# M030GAE register map
File version: 1.0
Registers are 32-bit, read-write, reset 0x0 unless marked. A register's access mark holds for its fields unless they carry their own. Offsets are from the block's base; [hi:lo] are bit positions; 'fields as' and 'values as' point back to an identical list.

## DAC2 — DAC Register Map
Base 0x4004B000
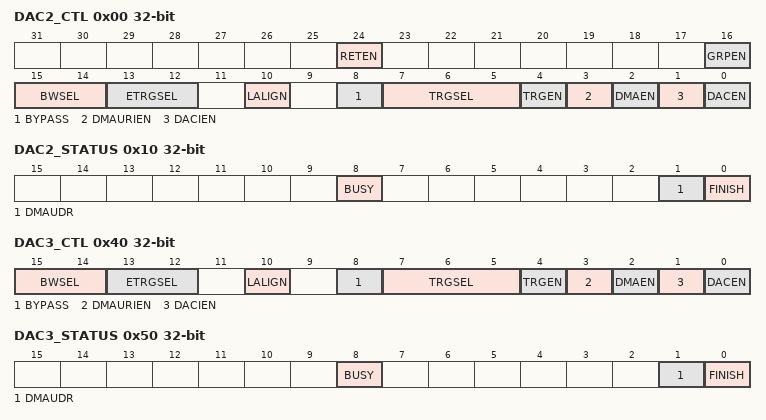
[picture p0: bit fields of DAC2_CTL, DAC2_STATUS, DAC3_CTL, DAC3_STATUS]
0x00 DAC2_CTL — DAC2 Control Register
  [24] RETEN — DAC Reset Retention Select (Write Protect). Note 1: This bit is write protected. Refer to the SYS_REGLCTL register. Note 2: This bit only exists in DAC0 control register to control 4 DAC retention.
    0=DAC controller registers reset by POR, NRESET, WDT, LVR, BOD, Lockup, CHIP and MCU reset sources; 1=DAC controller registers reset by POR, LVR, BOD and Lockup reset sources
  [16] GRPEN — DAC Group Mode Enable Bit
    0=DAC2 and DAC3 are not grouped; 1=DAC2 and DAC3 are grouped
  [15:14] BWSEL — DAC Data Bit-width Selection
    0=Data is 12 bits; 1=Data is 8 bits
  [13:12] ETRGSEL — External Pin Trigger Selection
    0=Low level trigger; 1=High level trigger; 2=Falling edge trigger; 3=Rising edge trigger
  [10] LALIGN — DAC Data Left-aligned Enabled Bit
    0=Right alignment; 1=Left alignment
  [8] BYPASS — Bypass Buffer Mode
    0=Output voltage buffer Enabled; 1=Output voltage buffer Disabled
  [7:5] TRGSEL — Trigger Source Selection
    0=Software trigger; 1=Timer 2 trigger; 2=Timer 0 trigger; 3=Timer 1 trigger; 4=Timer 3 trigger; 5=Timer 4 trigger; 6=BPWM 1 trigger; 7=Timer 5 trigger
  [4] TRGEN — Trigger Mode Enable Bit
    0=DAC event trigger mode Disabled; 1=DAC event trigger mode Enabled
  [3] DMAURIEN — DMA Under-run Interrupt Enable Bit
    0=DMA under-run interrupt Disabled; 1=DMA under-run interrupt Enabled
  [2] DMAEN — DMA Mode Enable Bit
    0=DMA mode Disabled; 1=DMA mode Enabled
  [1] DACIEN — DAC Interrupt Enable Bit
    0=DAC interrupt Disabled; 1=DAC interrupt Enabled
  [0] DACEN — DAC Enable Bit
    0=DAC Disabled; 1=DAC Enabled
0x04 DAC2_SWTRG — DAC2 Software Trigger Control Register
  [0] SWTRG — Software Trigger. Note: Writing this bit will generate one shot pulse and this bit is cleared to 0 by hardware automatically; reading this bit will always get 0.
    0=Software trigger Disabled; 1=Software trigger Enabled
0x08 DAC2_DAT — DAC2 Data Holding Register
  [15:0] DACDAT — DAC 12-bit Holding Data. These bits are written by user software which specifies 12-bit conversion data for DAC output. The unused bits (DAC2_DAT[3:0] in left-alignment mode and DAC2_DAT[15:12] in right alignment mode) are ignored by DAC controller hardware. 12 bit left alignment: user has to load data into DAC2_DAT[15:4] bits. 12 bit right alignment: user has to load data into DAC2_DAT[11:0] bits.
0x0C DAC2_DATOUT ro — DAC2 Data Output Register
  [11:0] DATOUT — DAC 12-bit Output Data. These bits are current digital data for DAC output conversion. It is loaded from DAC2_DAT register and user cannot write it directly.
0x10 DAC2_STATUS
  [8] BUSY ro — DAC Busy Flag (Read Only)
    0=DAC is ready for next conversion; 1=DAC is busy in conversion
  [1] DMAUDR — DMA Under-run Interrupt Flag. Note: Write 1 to clear this bit.
    0=No DMA under-run error condition occurred; 1=DMA under-run error condition occurred
  [0] FINISH — DAC Conversion Complete Finish Flag. Note: This bit is set to 1 when conversion time counter counts to SETTLET. It is cleared to 0 when DAC starts a new conversion. Write 1 to clear this bit to 0.
    0=DAC is in conversion state; 1=DAC conversion finish
0x14 DAC2_TCTL — DAC2 Timing Control Register
  [9:0] SETTLET — DAC Output Conversion Cycles. User software needs to write appropriate value to these bits to meet DAC conversion settling time based on PCLK (APB clock) speed. For example, DAC controller clock speed is 72 MHz and DAC conversion setting time is 1 us, and SETTLET value must be greater than 0x48. Note: The DAC output Conversion cycles is SETTLET + 1 PCLK cycles.
0x40 DAC3_CTL — DAC3 Control Register
  [15:14] BWSEL — DAC Data Bit-width Selection
    0=Data is 12 bits; 1=Data is 8 bits
  [13:12] ETRGSEL — External Pin Trigger Selection
    values as DAC2_CTL.ETRGSEL
  [10] LALIGN — DAC Data Left-aligned Enable Control
    0=Right alignment; 1=Left alignment
  [8] BYPASS — Bypass Buffer Mode
    values as DAC2_CTL.BYPASS
  [7:5] TRGSEL — Trigger Source Selection
    values as DAC2_CTL.TRGSEL
  [4] TRGEN — Trigger Mode Enable Bit
    values as DAC2_CTL.TRGEN
  [3] DMAURIEN — DMA Under-run Interrupt Enable Bit
    values as DAC2_CTL.DMAURIEN
  [2] DMAEN — DMA Mode Enable Bit
    0=DMA mode Disabled; 1=DMA mode Enabled
  [1] DACIEN — DAC Interrupt Enable Bit
    0=DAC interrupt Disabled; 1=DAC interrupt Enabled
  [0] DACEN — DAC Enable Bit
    0=DAC Disabled; 1=DAC Enabled
0x44 DAC3_SWTRG — DAC3 Software Trigger Control Register
  fields as DAC2_SWTRG
0x48 DAC3_DAT — DAC3 Data Holding Register
  [15:0] DACDAT — DAC 12-bit Holding Data. These bits are written by user software which specifies 12-bit conversion data for DAC output. The unused bits (DAC3_DAT[3:0] in left-alignment mode and DAC3_DAT[15:12] in right alignment mode) are ignored by DAC controller hardware. 12 bit left alignment: user has to load data into DAC3_DAT[15:4] bits. 12 bit right alignment: user has to load data into DAC3_DAT[11:0] bits.
0x4C DAC3_DATOUT ro — DAC3 Data Output Register
  [11:0] DATOUT — DAC 12-bit Output Data. These bits are current digital data for DAC output conversion. It is loaded from DAC3_DAT register and user cannot write it directly.
0x50 DAC3_STATUS
  [8] BUSY ro — DAC Busy Flag (Read Only)
    0=DAC is ready for the next conversion; 1=DAC is busy in conversion
  [1] DMAUDR — DMA Under-run Interrupt Flag. Note: Write 1 to clear this bit.
    values as DAC2_STATUS.DMAUDR
  [0] FINISH — DAC Conversion Complete Finish Flag. Note: This bit set to 1 when conversion time counter counts to SETTLET. It is cleared to 0 when DAC starts a new conversion. Write 1 to clear this bit to 0.
    0=DAC is in conversion state; 1=DAC conversion finished
0x54 DAC3_TCTL — DAC3 Timing Control Register
  [9:0] SETTLET — DAC Output Conversion Cycles. User software needs to write appropriate value to these bits to meet DAC conversion settling time based on PCLK (APB clock) speed. For example, DAC controller clock speed is 72 MHz and DAC conversion settling time is 1 us, and SETTLET value must be greater than 0x48. Note: The DAC output conversion cycles is SETTLET + 1 PCLK cycles.
